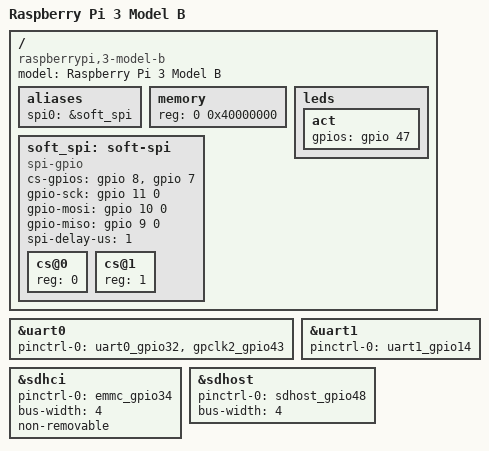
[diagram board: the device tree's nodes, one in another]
/dts-v1/;
#include "bcm2837.dtsi"
#include "bcm2835-rpi.dtsi"
#include "bcm283x-rpi-smsc9514.dtsi"
#include "bcm283x-rpi-usb-host.dtsi"

/ {
	compatible = "raspberrypi,3-model-b", "brcm,bcm2837";
	model = "Raspberry Pi 3 Model B";

	aliases {
		spi0 = &soft_spi;
	};

	memory {
		reg = <0 0x40000000>;
	};

	leds {
		act {
			gpios = <&gpio 47 0>;
		};
	};

	soft_spi: soft-spi {
		compatible = "spi-gpio";
		cs-gpios = <&gpio 8 0>, <&gpio 7 0>;
		gpio-sck = <&gpio 11 0>;	/* Y31 */
		gpio-mosi = <&gpio 10 0>;	/* Y33 */
		gpio-miso = <&gpio 9 0>;	/* Y30 */
		spi-delay-us = <1>;
		#address-cells = <1>;
		#size-cells = <0>;

		cs@0 {
			reg = <0>;
		};

		cs@1 {
			reg = <1>;
		};
	};
};

/* uart0 communicates with the BT module */
&uart0 {
	pinctrl-names = "default";
	pinctrl-0 = <&uart0_gpio32 &gpclk2_gpio43>;
	status = "okay";
};

/* uart1 is mapped to the pin header */
&uart1 {
	pinctrl-names = "default";
	pinctrl-0 = <&uart1_gpio14>;
	status = "okay";
};

/* SDHCI is used to control the SDIO for wireless */
&sdhci {
	pinctrl-names = "default";
	pinctrl-0 = <&emmc_gpio34>;
	status = "okay";
	bus-width = <4>;
	non-removable;
};

/* SDHOST is used to drive the SD card */
&sdhost {
	pinctrl-names = "default";
	pinctrl-0 = <&sdhost_gpio48>;
	status = "okay";
	bus-width = <4>;
};
